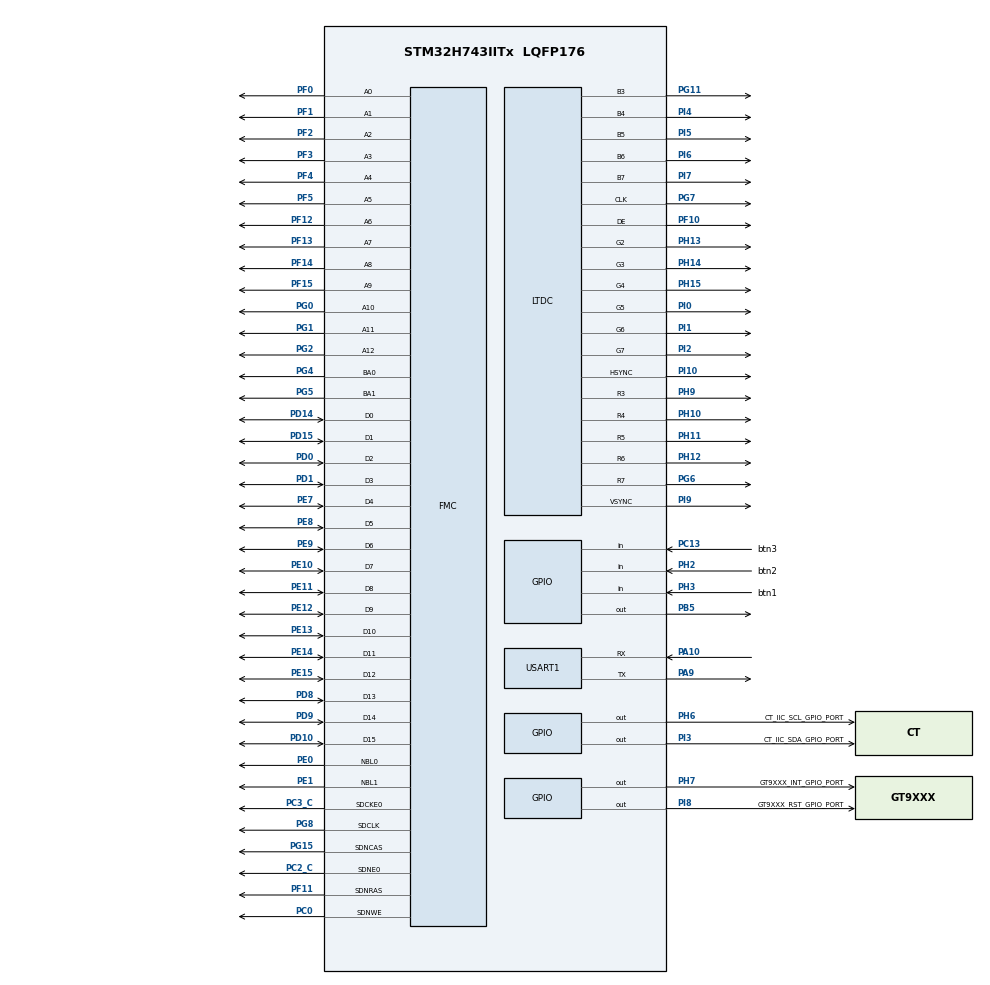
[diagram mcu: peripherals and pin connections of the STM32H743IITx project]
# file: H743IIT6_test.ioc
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CORTEX_M7.CPU_ICache=Disabled
CORTEX_M7.MPU_Control=__NULL
CORTEX_M7.default_mode_Activation=1
DMA2D.ColorMode=DMA2D_OUTPUT_RGB565
Dma.Request0=USART1_RX
Dma.Request1=USART1_TX
Dma.USART1_RX.0.Direction=DMA_PERIPH_TO_MEMORY
Dma.USART1_RX.0.EventEnable=DISABLE
Dma.USART1_RX.0.FIFOMode=DMA_FIFOMODE_DISABLE
Dma.USART1_RX.0.Instance=DMA1_Stream0
Dma.USART1_RX.0.MemDataAlignment=DMA_MDATAALIGN_BYTE
Dma.USART1_RX.0.MemInc=DMA_MINC_ENABLE
Dma.USART1_RX.0.Mode=DMA_NORMAL
Dma.USART1_RX.0.PeriphDataAlignment=DMA_PDATAALIGN_BYTE
Dma.USART1_RX.0.PeriphInc=DMA_PINC_DISABLE
Dma.USART1_RX.0.Polarity=HAL_DMAMUX_REQ_GEN_RISING
Dma.USART1_RX.0.Priority=DMA_PRIORITY_LOW
Dma.USART1_RX.0.RequestNumber=1
Dma.USART1_RX.0.SignalID=NONE
Dma.USART1_RX.0.SyncEnable=DISABLE
Dma.USART1_RX.0.SyncPolarity=HAL_DMAMUX_SYNC_NO_EVENT
Dma.USART1_RX.0.SyncRequestNumber=1
Dma.USART1_RX.0.SyncSignalID=NONE
Dma.USART1_TX.1.Direction=DMA_MEMORY_TO_PERIPH
Dma.USART1_TX.1.EventEnable=DISABLE
Dma.USART1_TX.1.FIFOMode=DMA_FIFOMODE_DISABLE
Dma.USART1_TX.1.Instance=DMA1_Stream1
Dma.USART1_TX.1.MemDataAlignment=DMA_MDATAALIGN_BYTE
Dma.USART1_TX.1.MemInc=DMA_MINC_ENABLE
Dma.USART1_TX.1.Mode=DMA_NORMAL
Dma.USART1_TX.1.PeriphDataAlignment=DMA_PDATAALIGN_BYTE
Dma.USART1_TX.1.PeriphInc=DMA_PINC_DISABLE
Dma.USART1_TX.1.Polarity=HAL_DMAMUX_REQ_GEN_RISING
Dma.USART1_TX.1.Priority=DMA_PRIORITY_LOW
Dma.USART1_TX.1.RequestNumber=1
Dma.USART1_TX.1.SignalID=NONE
Dma.USART1_TX.1.SyncEnable=DISABLE
Dma.USART1_TX.1.SyncPolarity=HAL_DMAMUX_SYNC_NO_EVENT
Dma.USART1_TX.1.SyncRequestNumber=1
Dma.USART1_TX.1.SyncSignalID=NONE
FMC.CASLatency1=FMC_SDRAM_CAS_LATENCY_2
FMC.ColumnBitsNumber1=FMC_SDRAM_COLUMN_BITS_NUM_9
FMC.ExitSelfRefreshDelay1=8
FMC.LoadToActiveDelay1=2
FMC.RCDDelay1=2
FMC.RPDelay1=2
FMC.RPDelay2=2
FMC.ReadBurst1=FMC_SDRAM_RBURST_ENABLE
FMC.ReadBurst2=FMC_SDRAM_RBURST_ENABLE
FMC.ReadPipeDelay1=FMC_SDRAM_RPIPE_DELAY_1
FMC.ReadPipeDelay2=FMC_SDRAM_RPIPE_DELAY_1
FMC.RowCycleDelay1=6
FMC.RowCycleDelay2=6
FMC.SDClockPeriod1=FMC_SDRAM_CLOCK_PERIOD_2
FMC.SDClockPeriod2=FMC_SDRAM_CLOCK_PERIOD_2
FMC.SelfRefreshTime1=6
FMC.WriteRecoveryTime1=4
LTDC.ActiveW=800
LTDC.Alpha0_L0=0
LTDC.Alpha0_L1=0
LTDC.Alpha_L0=255
LTDC.Alpha_L1=128
LTDC.BlendingFactor1_L0=LTDC_BLENDING_FACTOR1_CA
LTDC.BlendingFactor1_L1=LTDC_BLENDING_FACTOR1_CA
LTDC.BlendingFactor2_L0=LTDC_BLENDING_FACTOR2_CA
LTDC.BlendingFactor2_L1=LTDC_BLENDING_FACTOR2_CA
LTDC.Blue=0
LTDC.Blue_L0=0
LTDC.Blue_L1=0
LTDC.FBStartAdress_L0=Layer0_Buffer
LTDC.FBStartAdress_L1=Layer1_Buffer
LTDC.Green=0
LTDC.Green_L0=0
LTDC.Green_L1=0
LTDC.HBP=88
LTDC.HFP=40
LTDC.HSync=48
LTDC.ImageHeight_L0=480
LTDC.ImageHeight_L1=480
LTDC.ImageWidth_L0=800
LTDC.ImageWidth_L1=800
LTDC.Layers=1
LTDC.PCPolarity=LTDC_PCPOLARITY_IPC
LTDC.PixelFormat_L0=LTDC_PIXEL_FORMAT_RGB565
LTDC.PixelFormat_L1=LTDC_PIXEL_FORMAT_RGB565
LTDC.Red=0
LTDC.Red_L0=0
LTDC.Red_L1=0
LTDC.VBP=32
LTDC.VFP=13
LTDC.VSync=3
LTDC.WindowX1_L0=800
LTDC.WindowX1_L1=800
LTDC.WindowY1_L0=480
LTDC.WindowY1_L1=480
Mcu.Family=STM32H7
Mcu.Name=STM32H743IITx
Mcu.Package=LQFP176
NVIC.DMA1_Stream0_IRQn=true\:0\:0\:false\:false\:true\:false\:true\:true
NVIC.DMA1_Stream1_IRQn=true\:0\:0\:false\:false\:true\:false\:true\:true
NVIC.FMC_IRQn=true\:0\:0\:false\:false\:true\:true\:true\:true
NVIC.PriorityGroup=NVIC_PRIORITYGROUP_4
NVIC.TIM2_IRQn=true\:0\:0\:false\:false\:true\:true\:true\:true
NVIC.USART1_IRQn=true\:0\:0\:false\:false\:true\:true\:true\:true
PA10.Mode=Asynchronous
PA10.Signal=USART1_RX
PA13\ (JTMS/SWDIO).Mode=Serial_Wire
PA13\ (JTMS/SWDIO).Signal=DEBUG_JTMS-SWDIO
PA14\ (JTCK/SWCLK).Mode=Serial_Wire
PA14\ (JTCK/SWCLK).Signal=DEBUG_JTCK-SWCLK
PA9.Mode=Asynchronous
PA9.Signal=USART1_TX
PB5.PinState=GPIO_PIN_SET
PB5.Signal=GPIO_Output
PC0.Signal=FMC_SDNWE
PC13.GPIO_Label=btn3
PC13.GPIO_PuPd=GPIO_PULLUP
PC13.Signal=GPIO_Input
PC14-OSC32_IN\ (OSC32_IN).Mode=LSE-External-Oscillator
PC14-OSC32_IN\ (OSC32_IN).Signal=RCC_OSC32_IN
PC15-OSC32_OUT\ (OSC32_OUT).Mode=LSE-External-Oscillator
PC15-OSC32_OUT\ (OSC32_OUT).Signal=RCC_OSC32_OUT
PC2_C.Mode=SdramChipSelect1_1
PC2_C.Signal=FMC_SDNE0
PC3_C.Mode=SdramChipSelect1_1
PC3_C.Signal=FMC_SDCKE0
PD0.Signal=FMC_D2_DA2
PD1.Signal=FMC_D3_DA3
PD10.Signal=FMC_D15_DA15
PD14.Signal=FMC_D0_DA0
PD15.Signal=FMC_D1_DA1
PD8.Signal=FMC_D13_DA13
PD9.Signal=FMC_D14_DA14
PE0.Signal=FMC_NBL0
PE1.Signal=FMC_NBL1
PE10.Signal=FMC_D7_DA7
PE11.Signal=FMC_D8_DA8
PE12.Signal=FMC_D9_DA9
PE13.Signal=FMC_D10_DA10
PE14.Signal=FMC_D11_DA11
PE15.Signal=FMC_D12_DA12
PE7.Signal=FMC_D4_DA4
PE8.Signal=FMC_D5_DA5
PE9.Signal=FMC_D6_DA6
PF0.Signal=FMC_A0
PF1.Signal=FMC_A1
PF10.GPIO_Speed=GPIO_SPEED_FREQ_VERY_HIGH
PF10.Mode=RGB565
PF10.Signal=LTDC_DE
PF11.Signal=FMC_SDNRAS
PF12.Signal=FMC_A6
PF13.Signal=FMC_A7
PF14.Signal=FMC_A8
PF15.Signal=FMC_A9
PF2.Signal=FMC_A2
PF3.Signal=FMC_A3
PF4.Signal=FMC_A4
PF5.Signal=FMC_A5
PG0.Signal=FMC_A10
PG1.Signal=FMC_A11
PG11.GPIO_Speed=GPIO_SPEED_FREQ_VERY_HIGH
PG11.Mode=RGB565
PG11.Signal=LTDC_B3
PG15.Signal=FMC_SDNCAS
PG2.Signal=FMC_A12
PG4.Signal=FMC_A14_BA0
PG5.Signal=FMC_A15_BA1
PG6.GPIO_Speed=GPIO_SPEED_FREQ_VERY_HIGH
PG6.Mode=RGB565
PG6.Signal=LTDC_R7
PG7.GPIO_Speed=GPIO_SPEED_FREQ_VERY_HIGH
PG7.Mode=RGB565
PG7.Signal=LTDC_CLK
PG8.Signal=FMC_SDCLK
PH0-OSC_IN\ (PH0).Mode=HSE-External-Oscillator
PH0-OSC_IN\ (PH0).Signal=RCC_OSC_IN
PH1-OSC_OUT\ (PH1).Mode=HSE-External-Oscillator
PH1-OSC_OUT\ (PH1).Signal=RCC_OSC_OUT
PH10.GPIO_Speed=GPIO_SPEED_FREQ_VERY_HIGH
PH10.Mode=RGB565
PH10.Signal=LTDC_R4
PH11.GPIO_Speed=GPIO_SPEED_FREQ_VERY_HIGH
PH11.Mode=RGB565
PH11.Signal=LTDC_R5
PH12.GPIO_Speed=GPIO_SPEED_FREQ_VERY_HIGH
PH12.Mode=RGB565
PH12.Signal=LTDC_R6
PH13.GPIO_Speed=GPIO_SPEED_FREQ_VERY_HIGH
PH13.Mode=RGB565
PH13.Signal=LTDC_G2
PH14.GPIO_Speed=GPIO_SPEED_FREQ_VERY_HIGH
PH14.Mode=RGB565
PH14.Signal=LTDC_G3
PH15.GPIO_Speed=GPIO_SPEED_FREQ_VERY_HIGH
PH15.Mode=RGB565
PH15.Signal=LTDC_G4
PH2.GPIO_Label=btn2
PH2.GPIO_PuPd=GPIO_PULLUP
PH2.Signal=GPIO_Input
PH3.GPIO_Label=btn1
PH3.GPIO_PuPd=GPIO_PULLUP
PH3.Signal=GPIO_Input
PH6.GPIO_Label=CT_IIC_SCL_GPIO_PORT
PH6.GPIO_ModeDefaultOutputPP=GPIO_MODE_OUTPUT_PP
PH6.GPIO_PuPd=GPIO_PULLUP
PH6.GPIO_Speed=GPIO_SPEED_FREQ_HIGH
PH6.PinState=GPIO_PIN_RESET
PH6.Signal=GPIO_Output
PH7.GPIO_Label=GT9XXX_INT_GPIO_PORT
PH7.GPIO_Speed=GPIO_SPEED_FREQ_HIGH
PH7.Signal=GPIO_Output
PH9.GPIO_Speed=GPIO_SPEED_FREQ_VERY_HIGH
PH9.Mode=RGB565
PH9.Signal=LTDC_R3
PI0.GPIO_Speed=GPIO_SPEED_FREQ_VERY_HIGH
PI0.Mode=RGB565
PI0.Signal=LTDC_G5
PI1.GPIO_Speed=GPIO_SPEED_FREQ_VERY_HIGH
PI1.Mode=RGB565
PI1.Signal=LTDC_G6
PI10.GPIO_Speed=GPIO_SPEED_FREQ_VERY_HIGH
PI10.Mode=RGB565
PI10.Signal=LTDC_HSYNC
PI2.GPIO_Speed=GPIO_SPEED_FREQ_VERY_HIGH
PI2.Mode=RGB565
PI2.Signal=LTDC_G7
PI3.GPIO_Label=CT_IIC_SDA_GPIO_PORT
PI3.GPIO_PuPd=GPIO_PULLUP
PI3.GPIO_Speed=GPIO_SPEED_FREQ_HIGH
PI3.PinState=GPIO_PIN_RESET
PI3.Signal=GPIO_Output
PI4.GPIO_Speed=GPIO_SPEED_FREQ_VERY_HIGH
PI4.Mode=RGB565
PI4.Signal=LTDC_B4
PI5.GPIO_Speed=GPIO_SPEED_FREQ_VERY_HIGH
PI5.Mode=RGB565
PI5.Signal=LTDC_B5
PI6.GPIO_Speed=GPIO_SPEED_FREQ_VERY_HIGH
PI6.Mode=RGB565
PI6.Signal=LTDC_B6
PI7.GPIO_Speed=GPIO_SPEED_FREQ_VERY_HIGH
PI7.Mode=RGB565
PI7.Signal=LTDC_B7
PI8.GPIO_Label=GT9XXX_RST_GPIO_PORT
PI8.Signal=GPIO_Output
PI9.GPIO_Speed=GPIO_SPEED_FREQ_VERY_HIGH
PI9.Mode=RGB565
PI9.Signal=LTDC_VSYNC
ProjectManager.HeapSize=0x800
ProjectManager.StackSize=0x800
ProjectManager.TargetToolchain=STM32CubeIDE
RCC.ADCFreq_Value=220000000
RCC.APB1Freq_Value=120000000
RCC.APB2Freq_Value=120000000
RCC.APB3Freq_Value=120000000
RCC.APB4Freq_Value=120000000
RCC.CortexFreq_Value=480000000
RCC.D1PPRE=RCC_APB3_DIV2
RCC.D2PPRE1=RCC_APB1_DIV2
RCC.D2PPRE2=RCC_APB2_DIV2
RCC.D3PPRE=RCC_APB4_DIV2
RCC.DIVM1=5
RCC.DIVM2=25
RCC.DIVM3=25
RCC.DIVN1=192
RCC.DIVN2=440
RCC.DIVN3=396
RCC.DIVQ1=4
RCC.DIVR3=12
RCC.HCLKFreq_Value=240000000
RCC.HPRE=RCC_HCLK_DIV2
RCC.PLL2FRACN=0
RCC.PLL3FRACN=0
RCC.PLLFRACN=0
RCC.PLLSourceVirtual=RCC_PLLSOURCE_HSE
RCC.SYSCLKFreq_VALUE=480000000
RCC.SYSCLKSource=RCC_SYSCLKSOURCE_PLLCLK
RCC.USBFreq_Value=240000000
SH.FMC_A0.0=FMC_A0,13b-sda1
SH.FMC_A1.0=FMC_A1,13b-sda1
SH.FMC_A10.0=FMC_A10,13b-sda1
SH.FMC_A11.0=FMC_A11,13b-sda1
SH.FMC_A12.0=FMC_A12,13b-sda1
SH.FMC_A14_BA0.0=FMC_BA0,FourSdramBanks1
SH.FMC_A15_BA1.0=FMC_BA1,FourSdramBanks1
SH.FMC_A2.0=FMC_A2,13b-sda1
SH.FMC_A3.0=FMC_A3,13b-sda1
SH.FMC_A4.0=FMC_A4,13b-sda1
SH.FMC_A5.0=FMC_A5,13b-sda1
SH.FMC_A6.0=FMC_A6,13b-sda1
SH.FMC_A7.0=FMC_A7,13b-sda1
SH.FMC_A8.0=FMC_A8,13b-sda1
SH.FMC_A9.0=FMC_A9,13b-sda1
SH.FMC_D0_DA0.0=FMC_D0,sd-16b-d1
SH.FMC_D10_DA10.0=FMC_D10,sd-16b-d1
SH.FMC_D11_DA11.0=FMC_D11,sd-16b-d1
SH.FMC_D12_DA12.0=FMC_D12,sd-16b-d1
SH.FMC_D13_DA13.0=FMC_D13,sd-16b-d1
SH.FMC_D14_DA14.0=FMC_D14,sd-16b-d1
SH.FMC_D15_DA15.0=FMC_D15,sd-16b-d1
SH.FMC_D1_DA1.0=FMC_D1,sd-16b-d1
SH.FMC_D2_DA2.0=FMC_D2,sd-16b-d1
SH.FMC_D3_DA3.0=FMC_D3,sd-16b-d1
SH.FMC_D4_DA4.0=FMC_D4,sd-16b-d1
SH.FMC_D5_DA5.0=FMC_D5,sd-16b-d1
SH.FMC_D6_DA6.0=FMC_D6,sd-16b-d1
SH.FMC_D7_DA7.0=FMC_D7,sd-16b-d1
SH.FMC_D8_DA8.0=FMC_D8,sd-16b-d1
SH.FMC_D9_DA9.0=FMC_D9,sd-16b-d1
SH.FMC_NBL0.0=FMC_NBL0,Sd2ByteEnable1
SH.FMC_NBL1.0=FMC_NBL1,Sd2ByteEnable1
SH.FMC_SDCLK.0=FMC_SDCLK,13b-sda1
SH.FMC_SDNCAS.0=FMC_SDNCAS,13b-sda1
SH.FMC_SDNRAS.0=FMC_SDNRAS,13b-sda1
SH.FMC_SDNWE.0=FMC_SDNWE,13b-sda1
TIM2.Period=10000-1
TIM2.Prescaler=24000-1
USART1.VirtualMode-Asynchronous=VM_ASYNC
VP_DMA2D_VS_DMA2D.Mode=DMA2D_Activate
VP_MEMORYMAP_VS_MEMORYMAP.Mode=CurAppReg
VP_TIM2_VS_ClockSourceINT.Mode=Internal
board=custom

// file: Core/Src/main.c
/* USER CODE BEGIN Header */
/**
 ******************************************************************************
 * @file           : main.c
 * @brief          : Main program body
 ******************************************************************************
 * @attention
 *
 * Copyright (c) 2025 STMicroelectronics.
 * All rights reserved.
 *
 * This software is licensed under terms that can be found in the LICENSE file
 * in the root directory of this software component.
 * If no LICENSE file comes with this software, it is provided AS-IS.
 *
 ******************************************************************************
 */
/* USER CODE END Header */
#include "main.h"
#include "dma.h"
#include "dma2d.h"
#include "ltdc.h"
#include "tim.h"
#include "usart.h"
#include "gpio.h"
#include "fmc.h"

/* USER CODE BEGIN Includes */
#include "string.h"
#include"../inc/retarget.h"		//printf函数重映射
#include "../../User/Key/Button_event.h"
#include "../../User/W9825G6KH/W9825G6KH.h"
#include "../../User/RGBLCD/LCD.h"
#include "../../User/RGBLCD/IMG.h"
#include "../../User/TOUCH_GT9147/touch_gt9xxx.h"

/* USER CODE END Includes */

/* USER CODE BEGIN PV */

uint16_t fps = 0, fps_max = 0;

/* USER CODE END PV */

void SystemClock_Config(void);
/* USER CODE BEGIN PFP */

//SDRAM内存测试
void fsmc_sdram_test() {
	__IO uint32_t i = 0;
	__IO uint32_t temp = 0;
	__IO uint32_t sval = 0;	//在地址0读到的数据

	//每隔16K字节,写入一个数据,总共写入2048个数据,刚好是32M字节
	for (i = 0; i < 32 * 1024 * 1024; i += 16 * 1024) {
		*(__IO uint32_t*) (SDRAM_BANK_ADDR + i) = temp;
		temp++;
	}
	//依次读出之前写入的数据,进行校验
	for (i = 0; i < 32 * 1024 * 1024; i += 16 * 1024) {
		temp = *(__IO uint32_t*) (SDRAM_BANK_ADDR + i);
		if (i == 0)
			sval = temp;
		else if (temp <= sval)
			break;	//后面读出的数据一定要比第一次读到的数据大.
		printf("SDRAM Capacity:%dKB\r\n", (uint16_t) (temp - sval + 1) * 16);//打印SDRAM容量
	}
}

/* USER CODE END PFP */

/* USER CODE BEGIN 0 */

//重定义'定时器周期回调'函数
void HAL_TIM_PeriodElapsedCallback(TIM_HandleTypeDef *htim) {	//1S周期回调
	if (htim == &htim2) {
		if (fps_max - fps < -1 || fps_max - fps > 1) {
			fps_max = fps;
		}

		printf("H7");
		fps++;
	}
}

char receivData[50] = { 0 };	//存放接收内容(记得初始化)
uint8_t dataReady;	//发送标志位
//重定义'串口事件回调'函数
void HAL_UARTEx_RxEventCallback(UART_HandleTypeDef *huart, uint16_t Size) {
	if (huart == &huart1) {
		dataReady = 1;	//在主函数里处理发送

		//处理数据...

		HAL_UARTEx_ReceiveToIdle_DMA(&huart1, (uint8_t*) receivData, 50);
		__HAL_DMA_DISABLE_IT(&hdma_usart1_rx, DMA_IT_HT);	//关闭DMA接收过半中断
	}
}

/* USER CODE END 0 */

int main(void)
{

  /* MCU Configuration--------------------------------------------------------*/

  /* Reset of all peripherals, Initializes the Flash interface and the Systick. */
  HAL_Init();

  /* Configure the system clock */
  SystemClock_Config();

  /* Initialize all configured peripherals */
  MX_GPIO_Init();
  MX_DMA_Init();
  MX_TIM2_Init();
  MX_USART1_UART_Init();
  MX_FMC_Init();
  MX_LTDC_Init();
  MX_DMA2D_Init();
  /* USER CODE BEGIN 2 */

	RetargetInit(&huart1);	//将printf()函数映射到UART1串口上
	Button_Init();	//初始化按键
	HAL_TIM_Base_Start_IT(&htim2);	//开启定时

	SDRAM_InitSequence();	//W9825G6KH初始化
	gt9xxx_init();

	uint32_t RED=0xF800;  // 定义红色
	uint32_t WHITE=0xFFFF;// 定义白色
	uint32_t 黄色=0xffc0;  // 定义黄色
	uint32_t 蓝色=0x1155;  // 定义蓝色

	/* 防止SDRAM有残留数据 */
	FillRect_horizontal(0,0,800,480,0x0000,(uint32_t) LCD_Buffer0);
	FillRect_horizontal(0,0,800,480,0x0000,(uint32_t) LCD_Buffer1);

	// 填充背景色
	FillRect_horizontal(0,   0,   320, 240,  0xFFFF,(uint32_t) LCD_Buffer1);
	// 绘制数据条
	FillRect_horizontal(80,  80,  20,  120,  0x001f,(uint32_t) LCD_Buffer1);
	FillRect_horizontal(120, 100, 20,  100,  0x001f,(uint32_t) LCD_Buffer1);
	FillRect_horizontal(160, 40,  20,  160,  0x001f,(uint32_t) LCD_Buffer1);
	FillRect_horizontal(200, 60,  20,  140,  0x001f,(uint32_t) LCD_Buffer1);
	// 绘制X轴
	FillRect_horizontal(40,  200, 240, 1,    0x0000,(uint32_t) LCD_Buffer1);
	HAL_Delay(1000);

	FillRect_horizontal(0,0,800,480,0x0000,(uint32_t) LCD_Buffer0);
	FillRect_horizontal(0,0,800,480,0x0000,(uint32_t) LCD_Buffer1);

	// 填充背景色
	FillRect_vertical(0,   0,   320, 240,  0xFFFF,(uint32_t) LCD_Buffer1);
	// 绘制数据条(竖屏)
	FillRect_vertical(80,  80,  20,  120,  0x001f,(uint32_t) LCD_Buffer1);
	FillRect_vertical(120, 100, 20,  100,  0x001f,(uint32_t) LCD_Buffer1);
	FillRect_vertical(160, 40,  20,  160,  0x001f,(uint32_t) LCD_Buffer1);
	FillRect_vertical(200, 60,  20,  140,  0x001f,(uint32_t) LCD_Buffer1);
	// 绘制X轴
	FillRect_vertical(40,  200, 240, 1,    0x0000,(uint32_t) LCD_Buffer1);
	HAL_Delay(1000);
	FillRect_horizontal(0,0,800,480,0x0000,(uint32_t) LCD_Buffer0);
	FillRect_horizontal(0,0,800,480,0x0000,(uint32_t) LCD_Buffer1);

	/* 图片 */
	LTDC_Color_Fill(0,0,368,128,(uint16_t*)gImage_IMG,(uint32_t) LCD_Buffer1);

	HAL_Delay(1500);
	FillRect_horizontal(0,0,800,480,0x0000,(uint32_t) LCD_Buffer0);
	FillRect_horizontal(0,0,800,480,0x0000,(uint32_t) LCD_Buffer1);

	/* 方块混合图 */
	//横屏
	FillRect_horizontal(50,50,100,100,RED,(uint32_t) LCD_Buffer0);
	FillRect_horizontal(100,100,100,100,WHITE,(uint32_t) LCD_Buffer1);

	FillRect_horizontal(200,200,100,100,黄色,(uint32_t) LCD_Buffer0);
	FillRect_horizontal(250,250,100,100,蓝色,(uint32_t) LCD_Buffer1);

	//竖屏
	FillRect_vertical(0,0,100,100,WHITE,(uint32_t) LCD_Buffer1);
	FillRect_vertical(50,50,100,100,RED,(uint32_t) LCD_Buffer0);
	FillRect_vertical(0,800-100,100,100,黄色,(uint32_t) LCD_Buffer0);
	FillRect_vertical(50,800-150,100,100,蓝色,(uint32_t) LCD_Buffer1);

	HAL_Delay(1500);
	FillRect_horizontal(0,0,800,480,0x0000,(uint32_t) LCD_Buffer0);
	FillRect_horizontal(0,0,800,480,0x0000,(uint32_t) LCD_Buffer1);

	int temp = 0;
  /* USER CODE END 2 */

  /* Infinite loop */
  /* USER CODE BEGIN WHILE */
	while (1) {
		if (dataReady) {
			// 处理activeBuffer中的数据
			HAL_UART_Transmit_DMA(&huart1, (uint8_t*) receivData,strlen(receivData));
			dataReady = 0;
		}

		for(int i=0;i<3840;i+=10){
			gt9xxx_scan();
			Button_UPDATE();

			/* 横向移动 */
			FillRect_horizontal((50+i)%800,50,100,100,RED,(uint32_t) LCD_Buffer0);
			FillRect_horizontal((200+i)%800,200,100,100,黄色,(uint32_t) LCD_Buffer0);
			temp=(100-i)%800;
			if(temp<0){
				temp=800+temp;//超出范围回到最右边(最大处)
			}
			FillRect_horizontal(temp,100,100,100,WHITE,(uint32_t) LCD_Buffer1);
			temp=(250-i)%800;
			if(temp<0){
				temp=800+temp;////超出范围回到最右边(最大处)
			}
			FillRect_horizontal(temp,250,100,100,蓝色,(uint32_t) LCD_Buffer1);

			/* 竖向移动 */
			FillRect_vertical((0+i)%480,0,100,100,WHITE,(uint32_t) LCD_Buffer1);
			FillRect_vertical((50+i)%480,(800-150),100,100,蓝色,(uint32_t) LCD_Buffer1);

			temp=(50-i)%480;
			if(temp<0){
				temp=480+temp;////超出范围回到最右边(最大处)
			}
			FillRect_vertical(temp,50,100,100,RED,(uint32_t) LCD_Buffer0);
			temp=(0-i)%480;
			if(temp<0){
				temp=480+temp;////超出范围回到最右边(最大处)
			}
			FillRect_vertical(temp,(800-100),100,100,黄色,(uint32_t) LCD_Buffer0);

			HAL_Delay(30);

			FillRect_horizontal(0,0,800,480,0x0000,(uint32_t) LCD_Buffer0);
			FillRect_horizontal(0,0,800,480,0x0000,(uint32_t) LCD_Buffer1);
		}

    /* USER CODE END WHILE */

	}
}

void SystemClock_Config(void)
{
  RCC_OscInitTypeDef RCC_OscInitStruct = {0};
  RCC_ClkInitTypeDef RCC_ClkInitStruct = {0};

  /** Supply configuration update enable
  */
  HAL_PWREx_ConfigSupply(PWR_LDO_SUPPLY);

  /** Configure the main internal regulator output voltage
  */
  __HAL_PWR_VOLTAGESCALING_CONFIG(PWR_REGULATOR_VOLTAGE_SCALE0);

  while(!__HAL_PWR_GET_FLAG(PWR_FLAG_VOSRDY)) {}

  /** Initializes the RCC Oscillators according to the specified parameters
  * in the RCC_OscInitTypeDef structure.
  */
  RCC_OscInitStruct.OscillatorType = RCC_OSCILLATORTYPE_HSE;
  RCC_OscInitStruct.HSEState = RCC_HSE_ON;
  RCC_OscInitStruct.PLL.PLLState = RCC_PLL_ON;
  RCC_OscInitStruct.PLL.PLLSource = RCC_PLLSOURCE_HSE;
  RCC_OscInitStruct.PLL.PLLM = 5;
  RCC_OscInitStruct.PLL.PLLN = 192;
  RCC_OscInitStruct.PLL.PLLP = 2;
  RCC_OscInitStruct.PLL.PLLQ = 4;
  RCC_OscInitStruct.PLL.PLLR = 2;
  RCC_OscInitStruct.PLL.PLLRGE = RCC_PLL1VCIRANGE_2;
  RCC_OscInitStruct.PLL.PLLVCOSEL = RCC_PLL1VCOWIDE;
  RCC_OscInitStruct.PLL.PLLFRACN = 0;
  if (HAL_RCC_OscConfig(&RCC_OscInitStruct) != HAL_OK)
  {
    Error_Handler();
  }

  /** Initializes the CPU, AHB and APB buses clocks
  */
  RCC_ClkInitStruct.ClockType = RCC_CLOCKTYPE_HCLK|RCC_CLOCKTYPE_SYSCLK
                              |RCC_CLOCKTYPE_PCLK1|RCC_CLOCKTYPE_PCLK2
                              |RCC_CLOCKTYPE_D3PCLK1|RCC_CLOCKTYPE_D1PCLK1;
  RCC_ClkInitStruct.SYSCLKSource = RCC_SYSCLKSOURCE_PLLCLK;
  RCC_ClkInitStruct.SYSCLKDivider = RCC_SYSCLK_DIV1;
  RCC_ClkInitStruct.AHBCLKDivider = RCC_HCLK_DIV2;
  RCC_ClkInitStruct.APB3CLKDivider = RCC_APB3_DIV2;
  RCC_ClkInitStruct.APB1CLKDivider = RCC_APB1_DIV2;
  RCC_ClkInitStruct.APB2CLKDivider = RCC_APB2_DIV2;
  RCC_ClkInitStruct.APB4CLKDivider = RCC_APB4_DIV2;

  if (HAL_RCC_ClockConfig(&RCC_ClkInitStruct, FLASH_LATENCY_4) != HAL_OK)
  {
    Error_Handler();
  }
}

void Error_Handler(void)
{
	__disable_irq();
	while (1) {
	}
}
